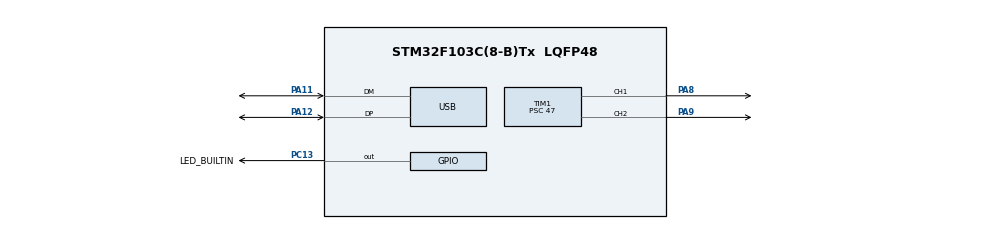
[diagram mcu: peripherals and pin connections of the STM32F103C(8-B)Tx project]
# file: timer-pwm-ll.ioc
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Mcu.Family=STM32F1
Mcu.Name=STM32F103C(8-B)Tx
Mcu.Package=LQFP48
NVIC.PriorityGroup=NVIC_PRIORITYGROUP_4
NVIC.USB_LP_CAN1_RX0_IRQn=true\:0\:0\:false\:false\:true\:false\:true
PA11.Mode=Device
PA11.Signal=USB_DM
PA12.Mode=Device
PA12.Signal=USB_DP
PA13.Mode=Serial_Wire
PA13.Signal=SYS_JTMS-SWDIO
PA14.Mode=Serial_Wire
PA14.Signal=SYS_JTCK-SWCLK
PA8.Signal=S_TIM1_CH1
PA9.Signal=S_TIM1_CH2
PC13-TAMPER-RTC.GPIO_Label=LED_BUILTIN
PC13-TAMPER-RTC.GPIO_ModeDefaultOutputPP=GPIO_MODE_OUTPUT_PP
PC13-TAMPER-RTC.GPIO_PuPd=GPIO_NOPULL
PC13-TAMPER-RTC.PinState=GPIO_PIN_SET
PC13-TAMPER-RTC.Signal=GPIO_Output
PC14-OSC32_IN.Mode=LSE-External-Oscillator
PC14-OSC32_IN.Signal=RCC_OSC32_IN
PC15-OSC32_OUT.Mode=LSE-External-Oscillator
PC15-OSC32_OUT.Signal=RCC_OSC32_OUT
PD0-OSC_IN.Mode=HSE-External-Oscillator
PD0-OSC_IN.Signal=RCC_OSC_IN
PD1-OSC_OUT.Mode=HSE-External-Oscillator
PD1-OSC_OUT.Signal=RCC_OSC_OUT
ProjectManager.HeapSize=0x200
ProjectManager.StackSize=0x400
ProjectManager.TargetToolchain=STM32CubeIDE
RCC.AHBFreq_Value=48000000
RCC.APB1CLKDivider=RCC_HCLK_DIV2
RCC.APB1Freq_Value=24000000
RCC.APB1TimFreq_Value=48000000
RCC.APB2Freq_Value=48000000
RCC.APB2TimFreq_Value=48000000
RCC.HCLKFreq_Value=48000000
RCC.PLLMUL=RCC_PLL_MUL6
RCC.PLLSourceVirtual=RCC_PLLSOURCE_HSE
RCC.SYSCLKFreq_VALUE=48000000
RCC.SYSCLKSource=RCC_SYSCLKSOURCE_PLLCLK
RCC.USBFreq_Value=48000000
SH.S_TIM1_CH1.0=TIM1_CH1,PWM Generation1 CH1
SH.S_TIM1_CH2.0=TIM1_CH2,PWM Generation2 CH2
TIM1.Channel-PWM\ Generation1\ CH1=TIM_CHANNEL_1
TIM1.Channel-PWM\ Generation2\ CH2=TIM_CHANNEL_2
TIM1.CounterMode=TIM_COUNTERMODE_UP
TIM1.OCMode_PWM-PWM\ Generation2\ CH2=TIM_OCMODE_PWM1
TIM1.Period=999
TIM1.Prescaler=47
TIM1.Pulse-PWM\ Generation1\ CH1=300
TIM1.Pulse-PWM\ Generation2\ CH2=700
USB_DEVICE.CLASS_NAME_FS=CDC
USB_DEVICE.VirtualMode=Cdc
USB_DEVICE.VirtualModeFS=Cdc_FS
VP_TIM1_VS_ClockSourceINT.Mode=Internal
VP_USB_DEVICE_VS_USB_DEVICE_CDC_FS.Mode=CDC_FS
board=custom

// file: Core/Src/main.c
/* USER CODE BEGIN Header */
/**
  ******************************************************************************
  * @file           : main.c
  * @brief          : Main program body
  ******************************************************************************
  * @attention
  *
  * <h2><center>&copy; Copyright (c) 2021 STMicroelectronics.
  * All rights reserved.</center></h2>
  *
  * This software component is licensed by ST under Ultimate Liberty license
  * SLA0044, the "License"; You may not use this file except in compliance with
  * the License. You may obtain a copy of the License at:
  *                             www.st.com/SLA0044
  *
  ******************************************************************************
  */
/* USER CODE END Header */
#include "main.h"
#include "usb_device.h"

void SystemClock_Config(void);
static void MX_GPIO_Init(void);
static void MX_TIM1_Init(void);

int main(void)
{

  /* MCU Configuration--------------------------------------------------------*/

  /* Reset of all peripherals, Initializes the Flash interface and the Systick. */
  HAL_Init();

  /* Configure the system clock */
  SystemClock_Config();

  /* Initialize all configured peripherals */
  MX_GPIO_Init();
  MX_USB_DEVICE_Init();
  MX_TIM1_Init();

  /* Infinite loop */
  /* USER CODE BEGIN WHILE */

  // Enable Ch1 and Ch2
  LL_TIM_CC_EnableChannel(TIM1, TIM_CCER_CC1E | TIM_CCER_CC2E);
  // Enable outputs by setting MOE (master output enable) bit high in BDTR (break and dead-time reg)
  LL_TIM_EnableAllOutputs(TIM1);
  // Enable the timer (CEN bit in CR1)
  LL_TIM_EnableCounter(TIM1);

  while (1)
  {
	  for (uint32_t i = 0; i < 1000; i +=10 ){
		  LL_TIM_OC_SetCompareCH1(TIM1, i);
		  LL_TIM_OC_SetCompareCH2(TIM1, 1000-i);
		  HAL_Delay(20);
	  }
	  for (uint32_t i = 0; i < 1000; i +=10 ){
		  LL_TIM_OC_SetCompareCH1(TIM1, 1000-i);
		  LL_TIM_OC_SetCompareCH2(TIM1, i);
		  HAL_Delay(20);
	  }
    /* USER CODE END WHILE */

  }
}

void SystemClock_Config(void)
{
  LL_FLASH_SetLatency(LL_FLASH_LATENCY_1);
  while(LL_FLASH_GetLatency()!= LL_FLASH_LATENCY_1)
  {
  }
  LL_RCC_HSE_Enable();

   /* Wait till HSE is ready */
  while(LL_RCC_HSE_IsReady() != 1)
  {

  }
  LL_RCC_PLL_ConfigDomain_SYS(LL_RCC_PLLSOURCE_HSE_DIV_1, LL_RCC_PLL_MUL_6);
  LL_RCC_PLL_Enable();

   /* Wait till PLL is ready */
  while(LL_RCC_PLL_IsReady() != 1)
  {

  }
  LL_RCC_SetAHBPrescaler(LL_RCC_SYSCLK_DIV_1);
  LL_RCC_SetAPB1Prescaler(LL_RCC_APB1_DIV_2);
  LL_RCC_SetAPB2Prescaler(LL_RCC_APB2_DIV_1);
  LL_RCC_SetSysClkSource(LL_RCC_SYS_CLKSOURCE_PLL);

   /* Wait till System clock is ready */
  while(LL_RCC_GetSysClkSource() != LL_RCC_SYS_CLKSOURCE_STATUS_PLL)
  {

  }
  LL_SetSystemCoreClock(48000000);

   /* Update the time base */
  if (HAL_InitTick (TICK_INT_PRIORITY) != HAL_OK)
  {
    Error_Handler();
  }
  LL_RCC_SetUSBClockSource(LL_RCC_USB_CLKSOURCE_PLL);
}

static void MX_TIM1_Init(void)
{

  LL_TIM_InitTypeDef TIM_InitStruct = {0};
  LL_TIM_OC_InitTypeDef TIM_OC_InitStruct = {0};
  LL_TIM_BDTR_InitTypeDef TIM_BDTRInitStruct = {0};

  LL_GPIO_InitTypeDef GPIO_InitStruct = {0};

  /* Peripheral clock enable */
  LL_APB2_GRP1_EnableClock(LL_APB2_GRP1_PERIPH_TIM1);

  TIM_InitStruct.Prescaler = 47;
  TIM_InitStruct.CounterMode = LL_TIM_COUNTERMODE_UP;
  TIM_InitStruct.Autoreload = 999;
  TIM_InitStruct.ClockDivision = LL_TIM_CLOCKDIVISION_DIV1;
  TIM_InitStruct.RepetitionCounter = 0;
  LL_TIM_Init(TIM1, &TIM_InitStruct);
  LL_TIM_DisableARRPreload(TIM1);
  LL_TIM_SetClockSource(TIM1, LL_TIM_CLOCKSOURCE_INTERNAL);
  LL_TIM_OC_EnablePreload(TIM1, LL_TIM_CHANNEL_CH1);
  TIM_OC_InitStruct.OCMode = LL_TIM_OCMODE_PWM1;
  TIM_OC_InitStruct.OCState = LL_TIM_OCSTATE_DISABLE;
  TIM_OC_InitStruct.OCNState = LL_TIM_OCSTATE_DISABLE;
  TIM_OC_InitStruct.CompareValue = 300;
  TIM_OC_InitStruct.OCPolarity = LL_TIM_OCPOLARITY_HIGH;
  TIM_OC_InitStruct.OCNPolarity = LL_TIM_OCPOLARITY_HIGH;
  TIM_OC_InitStruct.OCIdleState = LL_TIM_OCIDLESTATE_LOW;
  TIM_OC_InitStruct.OCNIdleState = LL_TIM_OCIDLESTATE_LOW;
  LL_TIM_OC_Init(TIM1, LL_TIM_CHANNEL_CH1, &TIM_OC_InitStruct);
  LL_TIM_OC_DisableFast(TIM1, LL_TIM_CHANNEL_CH1);
  LL_TIM_OC_EnablePreload(TIM1, LL_TIM_CHANNEL_CH2);
  TIM_OC_InitStruct.OCState = LL_TIM_OCSTATE_DISABLE;
  TIM_OC_InitStruct.OCNState = LL_TIM_OCSTATE_DISABLE;
  TIM_OC_InitStruct.CompareValue = 700;
  LL_TIM_OC_Init(TIM1, LL_TIM_CHANNEL_CH2, &TIM_OC_InitStruct);
  LL_TIM_OC_DisableFast(TIM1, LL_TIM_CHANNEL_CH2);
  LL_TIM_SetTriggerOutput(TIM1, LL_TIM_TRGO_RESET);
  LL_TIM_DisableMasterSlaveMode(TIM1);
  TIM_BDTRInitStruct.OSSRState = LL_TIM_OSSR_DISABLE;
  TIM_BDTRInitStruct.OSSIState = LL_TIM_OSSI_DISABLE;
  TIM_BDTRInitStruct.LockLevel = LL_TIM_LOCKLEVEL_OFF;
  TIM_BDTRInitStruct.DeadTime = 0;
  TIM_BDTRInitStruct.BreakState = LL_TIM_BREAK_DISABLE;
  TIM_BDTRInitStruct.BreakPolarity = LL_TIM_BREAK_POLARITY_HIGH;
  TIM_BDTRInitStruct.AutomaticOutput = LL_TIM_AUTOMATICOUTPUT_DISABLE;
  LL_TIM_BDTR_Init(TIM1, &TIM_BDTRInitStruct);
  LL_APB2_GRP1_EnableClock(LL_APB2_GRP1_PERIPH_GPIOA);
  /**TIM1 GPIO Configuration
  PA8   ------> TIM1_CH1
  PA9   ------> TIM1_CH2
  */
  GPIO_InitStruct.Pin = LL_GPIO_PIN_8|LL_GPIO_PIN_9;
  GPIO_InitStruct.Mode = LL_GPIO_MODE_ALTERNATE;
  GPIO_InitStruct.Speed = LL_GPIO_SPEED_FREQ_LOW;
  GPIO_InitStruct.OutputType = LL_GPIO_OUTPUT_PUSHPULL;
  LL_GPIO_Init(GPIOA, &GPIO_InitStruct);

}

static void MX_GPIO_Init(void)
{
  LL_GPIO_InitTypeDef GPIO_InitStruct = {0};

  /* GPIO Ports Clock Enable */
  LL_APB2_GRP1_EnableClock(LL_APB2_GRP1_PERIPH_GPIOC);
  LL_APB2_GRP1_EnableClock(LL_APB2_GRP1_PERIPH_GPIOD);
  LL_APB2_GRP1_EnableClock(LL_APB2_GRP1_PERIPH_GPIOA);

  /**/
  LL_GPIO_SetOutputPin(LED_BUILTIN_GPIO_Port, LED_BUILTIN_Pin);

  /**/
  GPIO_InitStruct.Pin = LED_BUILTIN_Pin;
  GPIO_InitStruct.Mode = LL_GPIO_MODE_OUTPUT;
  GPIO_InitStruct.Speed = LL_GPIO_SPEED_FREQ_LOW;
  GPIO_InitStruct.OutputType = LL_GPIO_OUTPUT_PUSHPULL;
  LL_GPIO_Init(LED_BUILTIN_GPIO_Port, &GPIO_InitStruct);

}

void Error_Handler(void)
{
}

/************************ (C) COPYRIGHT STMicroelectronics *****END OF FILE****/
